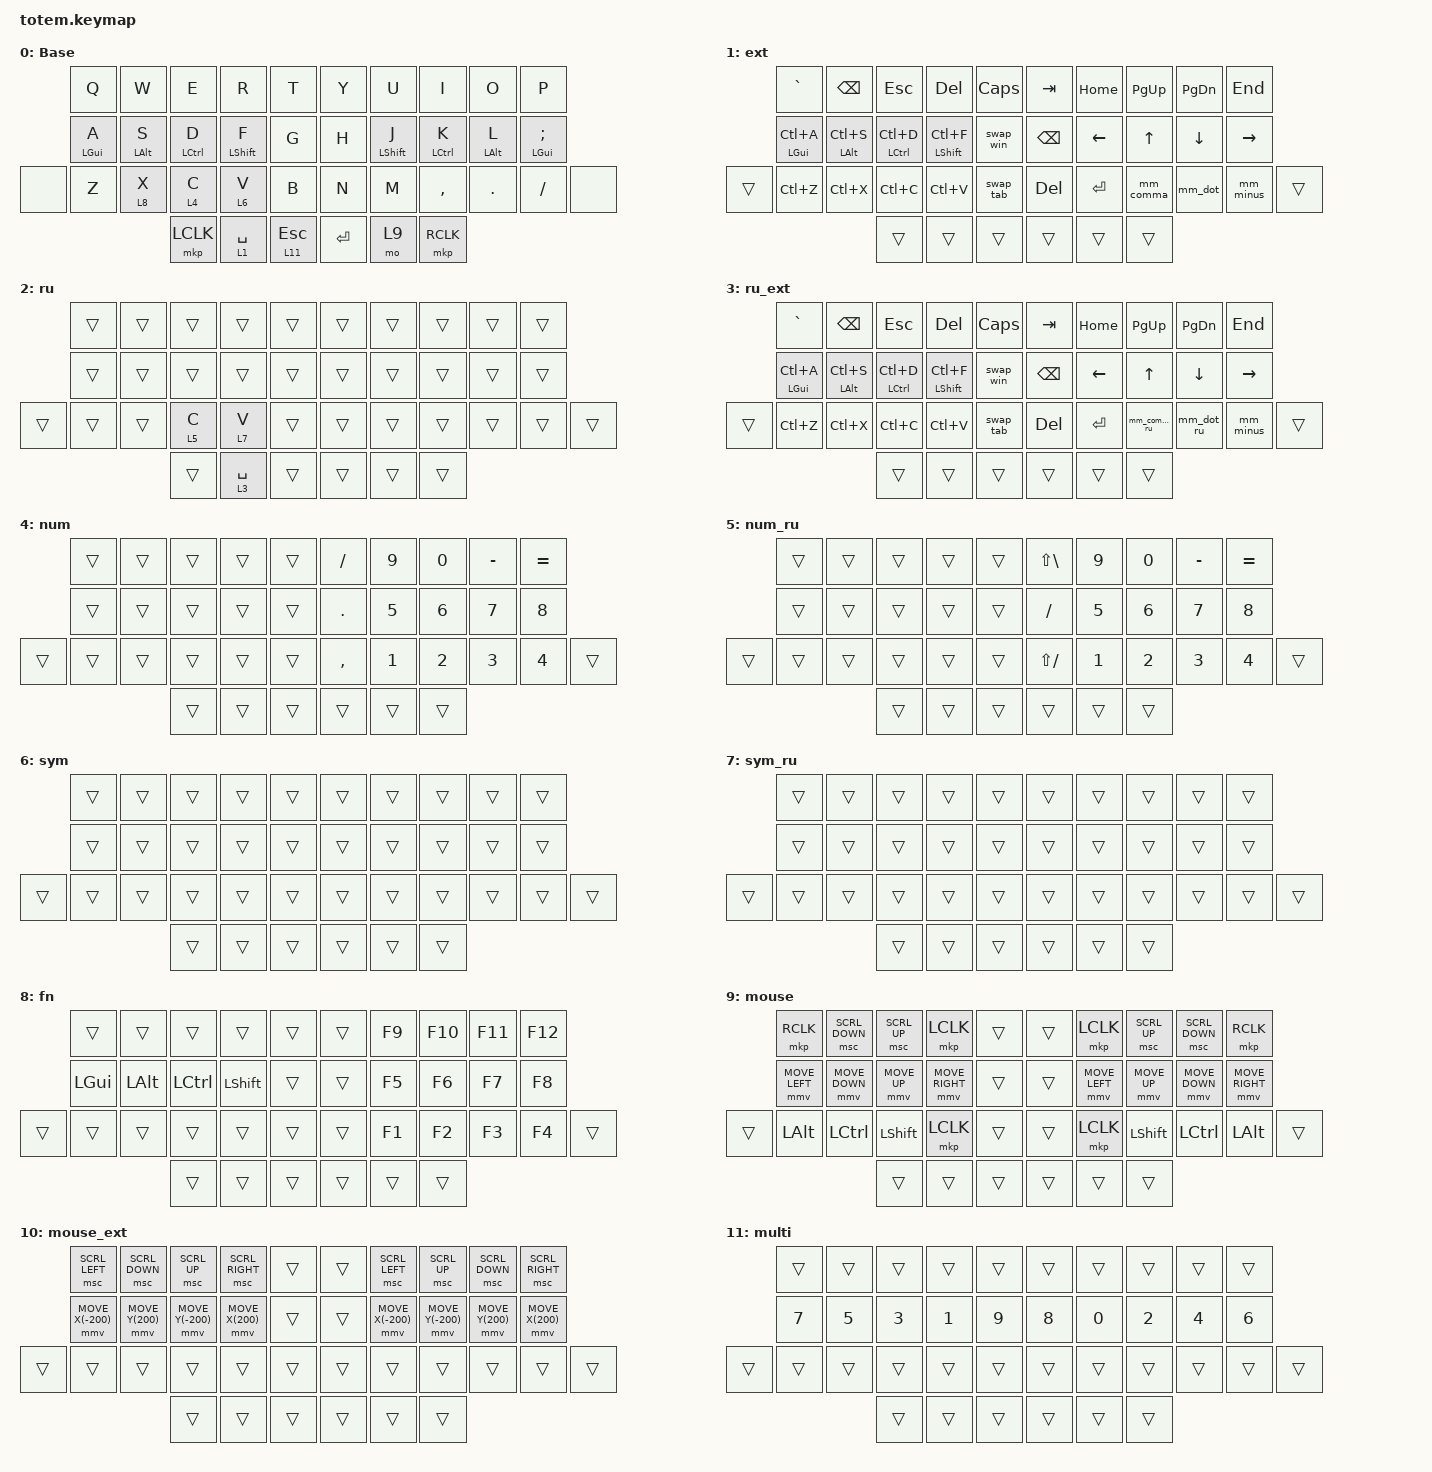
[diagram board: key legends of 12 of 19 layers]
//
//                                                        ▀▀▀▀▀     ▀▀▀▀▀          ▀▀█▀▀
//                                                        ▄▀▀▀▄  ▄  ▄▀▀▀▄  ▄  ▄▀▀▀▄  █  ▄▀▀▀▄
//                                                        █   █  █  █   █  █  █   █  █  █   █
//                                                         ▀▀▀   █   ▀▀▀   █   ▀▀▀   ▀   ▀▀▀
//                                                               █      ▄▄▄█▄▄▄    █   █
//                                                               ▀      █  █  █     █▄█
//                                                             ▀▀▀▀▀    █  █  █      ▀
//                                                                      ▀  ▀  ▀
//
// ▄▄▄▄▄▄▄▄▄▄▄▄▄▄▄▄▄▄▄▄▄▄▄▄▄▄▄▄▄▄▄▄▄▄▄▄▄▄▄▄▄▄▄▄▄▄▄▄▄▄▄▄▄▄▄▄▄▄▄▄▄▄▄▄▄▄▄▄▄▄▄▄▄▄▄▄▄▄▄▄▄▄▄▄▄▄▄▄▄▄▄▄▄▄▄▄▄▄▄▄▄▄▄▄▄▄▄▄▄▄▄▄▄▄▄▄▄▄▄▄▄▄▄▄▄▄▄▄▄▄▄▄▄▄▄▄▄▄▄▄▄▄▄▄▄▄▄▄▄

#define ZMK_POINTING_DEFAULT_MOVE_VAL 1200  // default: 600
#define ZMK_POINTING_DEFAULT_SCRL_VAL 20    // default: 10

#include <behaviors.dtsi>
#include <dt-bindings/zmk/keys.h>
#include <dt-bindings/zmk/pointing.h>

&mt {
    quick-tap-ms = <100>;
    global-quick-tap;
    flavor = "tap-preferred";
    tapping-term-ms = <170>;
};

&lt {
    tapping-term-ms = <240>;
    flavor = "balanced";
    quick-tap-ms = <150>;
};

/ {
    behaviors {
        tp: tap_preferred {
            compatible = "zmk,behavior-hold-tap";
            label = "TAP_PREFERRED";
            #binding-cells = <2>;
            tapping-term-ms = <150>;
            quick-tap-ms = <0>;
            flavor = "tap-preferred";
            bindings = <&kp>, <&kp>;
        };

        hml: home_row_mod_left {
            compatible = "zmk,behavior-hold-tap";
            #binding-cells = <2>;
            flavor = "balanced";
            require-prior-idle-ms = <150>;
            tapping-term-ms = <280>;
            quick-tap-ms = <175>;
            bindings = <&kp>, <&kp>;

            hold-trigger-key-positions = <5 6 7 8 9 9 15 16 18 19 26 27 28 29 30 31 35 36 37 17>;
            hold-trigger-on-release;
        };

        hmr: home_row_mod_right {
            compatible = "zmk,behavior-hold-tap";
            #binding-cells = <2>;
            flavor = "balanced";
            require-prior-idle-ms = <150>;
            tapping-term-ms = <280>;
            quick-tap-ms = <175>;
            bindings = <&kp>, <&kp>;

            hold-trigger-key-positions = <20 21 0 10 22 11 1 2 12 23 3 4 13 14 24 24 25 33 32 34>;
            hold-trigger-on-release;
        };

        num_word: num_word {
            compatible = "zmk,behavior-auto-layer";
            #binding-cells = <1>;
            continue-list = <BSPC DEL DOT COMMA PLUS MINUS STAR FSLH EQUAL>;
            ignore-numbers;
        };

        mm_comma: mm_comma {
            compatible = "zmk,behavior-mod-morph";
            label = "MM_COMMA";
            bindings = <&macro_comma>, <&kp SEMI>;

            #binding-cells = <0>;
            mods = <(MOD_LSFT|MOD_RSFT)>;
        };

        mm_comma_ru: mm_comma_ru {
            compatible = "zmk,behavior-mod-morph";
            label = "MM_COMMA_RU";
            bindings = <&macro_comma_ru>, <&kp SEMI>;

            #binding-cells = <0>;
            mods = <(MOD_LSFT|MOD_RSFT)>;
        };

        mm_dot: mm_dot {
            compatible = "zmk,behavior-mod-morph";
            label = "MM_DOT";
            bindings = <&macro_dot>, <&kp LS(SEMI)>;

            #binding-cells = <0>;
            mods = <(MOD_LSFT|MOD_RSFT)>;
        };

        mm_dot_ru: mm_dot_ru {
            compatible = "zmk,behavior-mod-morph";
            label = "MM_DOT_RU";
            bindings = <&macro_dot_ru>, <&kp LS(SEMI)>;

            #binding-cells = <0>;
            mods = <(MOD_LSFT|MOD_RSFT)>;
        };

        mm_minus: mm_minus {
            compatible = "zmk,behavior-mod-morph";
            label = "MM_MINUS";
            bindings = <&kp MINUS>, <&kp MINUS>;

            #binding-cells = <0>;
            mods = <(MOD_LSFT|MOD_RSFT)>;
        };

        swap_win: swapper_win {
            compatible = "zmk,behavior-tri-state";
            label = "SWAPPER_WIN";
            #binding-cells = <0>;
            bindings = <&kt LALT>, <&kp TAB>, <&kt LALT>;

            ignored-key-positions = <13>;
        };

        swap_tab: swapper_tab {
            compatible = "zmk,behavior-tri-state";
            label = "SWAPPER_TAB";
            #binding-cells = <0>;
            bindings = <&kt LCTRL>, <&kp TAB>, <&kt LCTRL>;

            ignored-key-positions = <13>;
        };
    };

    macros {
        macro_comma: macro_comma {
            compatible = "zmk,behavior-macro";
            #binding-cells = <0>;
            bindings = <&kp COMMA &kp SPACE>;
            label = "MACRO_COMMA";
        };

        macro_comma_ru: macro_comma_ru {
            compatible = "zmk,behavior-macro";
            #binding-cells = <0>;
            bindings = <&kp LS(SLASH) &kp SPACE>;
            label = "MACRO_COMMA_RU";
        };

        macro_dot: macro_dot {
            compatible = "zmk,behavior-macro";
            #binding-cells = <0>;
            bindings = <&kp DOT &kp SPACE &sk LSHFT>;
            label = "MACRO_DOT";
        };

        macro_dot_ru: macro_dot_ru {
            compatible = "zmk,behavior-macro";
            #binding-cells = <0>;
            bindings = <&kp SLASH &kp SPACE &sk LSHFT>;
            label = "MACRO_DOT_RU";
        };

        macro_lng: macro_lng {
            compatible = "zmk,behavior-macro";
            #binding-cells = <0>;
            bindings = <&kp CAPS &tog 2>;
            label = "MACRO_LNG";
        };

        macro_lng_en: macro_lng_sync {
            compatible = "zmk,behavior-macro";
            #binding-cells = <0>;
            bindings = <&kp CAPS &to 0>;
            label = "MACRO_LNG_SYNC";
        };

        macro_lt: macro_lt {
            compatible = "zmk,behavior-macro";
            #binding-cells = <0>;
            bindings = <&kp CAPS &kp LS(COMMA) &kp CAPS>;
            label = "MACRO_LT";
        };

        macro_gt: macro_gt {
            compatible = "zmk,behavior-macro";
            #binding-cells = <0>;
            bindings = <&kp CAPS &kp LS(DOT) &kp CAPS>;
            label = "MACRO_GT";
        };
    };

    combos {
        compatible = "zmk,combos";

        combo_lng_l {
            bindings = <&macro_lng>;
            key-positions = <3 13>;
        };

        combo_lng_r {
            bindings = <&macro_lng>;
            key-positions = <6 16>;
        };

        combo_esc {
            bindings = <&kp ESC>;
            key-positions = <2 12>;
        };

        combo_ret {
            bindings = <&kp RET>;
            key-positions = <16 27>;
        };

        combo_bspc {
            bindings = <&kp BACKSPACE>;
            key-positions = <15 16>;
        };

        combo_spc {
            bindings = <&kp SPACE>;
            key-positions = <13 24>;
        };

        combo_num_word_en {
            bindings = <&num_word 4>;
            key-positions = <7 17>;
            layers = <0>;
        };

        combo_caps_word {
            bindings = <&caps_word>;
            key-positions = <8 18>;
        };

        combo_ins {
            bindings = <&kp INS>;
            key-positions = <15 26>;
        };

        combo_mouse_l {
            bindings = <&tog 3>;
            key-positions = <3 4>;
        };

        combo_mouse_r {
            bindings = <&tog 3>;
            key-positions = <6 5>;
        };

        combo_num_word_ru {
            bindings = <&num_word 5>;
            key-positions = <17 7>;
            layers = <15>;
        };

        combo_lbkt {
            bindings = <&kp LBKT>;
            key-positions = <9 8>;
        };

        combo_sqt {
            bindings = <&kp SQT>;
            key-positions = <18 19>;
        };

        combo_rbkt {
            bindings = <&kp RBKT>;
            key-positions = <29 30>;
        };
    };

    keymap {
        compatible = "zmk,keymap";

        Base {
            display-name = "Base";
            bindings = <
       &kp Q        &kp W        &kp E         &kp R          &kp T         &kp Y    &kp U         &kp I         &kp O        &kp P
       &hml LGUI A  &hml LALT S  &hml LCTRL D  &hml LSHIFT F  &kp G         &kp H    &hmr LSHFT J  &hmr LCTRL K  &hmr LALT L  &hmr LGUI SEMICOLON
&none  &kp Z        &lt 8 X      &lt 4 C       &lt 6 V        &kp B         &kp N    &kp M         &kp COMMA     &kp DOT      &kp SLASH            &none
                                 &mkp LCLK     &lt 1 SPACE    &lt 11 ESC    &kp RET  &mo 9         &mkp RCLK
            >;
        };

        ext {
            bindings = <
        &kp GRAVE       &kp BACKSPACE   &kp ESC          &kp DEL          &kp CAPS     &kp TAB        &kp HOME  &kp PG_UP  &kp PG_DN  &kp END
        &tp LGUI LC(A)  &tp LALT LC(S)  &tp LCTRL LC(D)  &tp LSHFT LC(F)  &swap_win    &kp BACKSPACE  &kp LEFT  &kp UP     &kp DOWN   &kp RIGHT
&trans  &kp LC(Z)       &kp LC(X)       &kp LC(C)        &kp LC(V)        &swap_tab    &kp DEL        &kp RET   &mm_comma  &mm_dot    &mm_minus  &trans
                                        &trans           &trans           &trans       &trans         &trans    &trans
            >;
        };

        ru {
            bindings = <
        &trans  &trans  &trans   &trans       &trans    &trans  &trans  &trans  &trans  &trans
        &trans  &trans  &trans   &trans       &trans    &trans  &trans  &trans  &trans  &trans
&trans  &trans  &trans  &lt 5 C  &lt 7 V      &trans    &trans  &trans  &trans  &trans  &trans  &trans
                        &trans   &lt 3 SPACE  &trans    &trans  &trans  &trans
            >;
        };

        ru_ext {
            bindings = <
        &kp GRAVE       &kp BACKSPACE   &kp ESC          &kp DEL          &kp CAPS     &kp TAB        &kp HOME  &kp PG_UP     &kp PG_DN   &kp END
        &tp LGUI LC(A)  &tp LALT LC(S)  &tp LCTRL LC(D)  &tp LSHFT LC(F)  &swap_win    &kp BACKSPACE  &kp LEFT  &kp UP        &kp DOWN    &kp RIGHT
&trans  &kp LC(Z)       &kp LC(X)       &kp LC(C)        &kp LC(V)        &swap_tab    &kp DEL        &kp RET   &mm_comma_ru  &mm_dot_ru  &mm_minus  &trans
                                        &trans           &trans           &trans       &trans         &trans    &trans
            >;
        };

        num {
            bindings = <
        &trans  &trans  &trans  &trans  &trans    &kp SLASH  &kp N9  &kp N0  &kp MINUS  &kp EQUAL
        &trans  &trans  &trans  &trans  &trans    &kp DOT    &kp N5  &kp N6  &kp N7     &kp N8
&trans  &trans  &trans  &trans  &trans  &trans    &kp COMMA  &kp N1  &kp N2  &kp N3     &kp N4     &trans
                        &trans  &trans  &trans    &trans     &trans  &trans
            >;
        };

        num_ru {
            bindings = <
        &trans  &trans  &trans  &trans  &trans    &kp LS(BACKSLASH)  &kp N9  &kp N0  &kp MINUS  &kp EQUAL
        &trans  &trans  &trans  &trans  &trans    &kp SLASH          &kp N5  &kp N6  &kp N7     &kp N8
&trans  &trans  &trans  &trans  &trans  &trans    &kp LS(SLASH)      &kp N1  &kp N2  &kp N3     &kp N4     &trans
                        &trans  &trans  &trans    &trans             &trans  &trans
            >;
        };

        sym {
            bindings = <
        &trans  &trans  &trans  &trans  &trans    &trans  &trans  &trans  &trans  &trans
        &trans  &trans  &trans  &trans  &trans    &trans  &trans  &trans  &trans  &trans
&trans  &trans  &trans  &trans  &trans  &trans    &trans  &trans  &trans  &trans  &trans  &trans
                        &trans  &trans  &trans    &trans  &trans  &trans
            >;
        };

        sym_ru {
            bindings = <
        &trans  &trans  &trans  &trans  &trans    &trans  &trans  &trans  &trans  &trans
        &trans  &trans  &trans  &trans  &trans    &trans  &trans  &trans  &trans  &trans
&trans  &trans  &trans  &trans  &trans  &trans    &trans  &trans  &trans  &trans  &trans  &trans
                        &trans  &trans  &trans    &trans  &trans  &trans
            >;
        };

        fn {
            bindings = <
        &trans    &trans    &trans     &trans     &trans    &trans  &kp F9  &kp F10  &kp F11  &kp F12
        &kp LGUI  &kp LALT  &kp LCTRL  &kp LSHFT  &trans    &trans  &kp F5  &kp F6   &kp F7   &kp F8
&trans  &trans    &trans    &trans     &trans     &trans    &trans  &kp F1  &kp F2   &kp F3   &kp F4   &trans
                            &trans     &trans     &trans    &trans  &trans  &trans
            >;
        };

        mouse {
            bindings = <
        &mkp RCLK       &msc SCRL_DOWN  &msc SCRL_UP  &mkp LCLK        &trans    &trans  &mkp LCLK       &msc SCRL_UP  &msc SCRL_DOWN  &mkp RCLK
        &mmv MOVE_LEFT  &mmv MOVE_DOWN  &mmv MOVE_UP  &mmv MOVE_RIGHT  &trans    &trans  &mmv MOVE_LEFT  &mmv MOVE_UP  &mmv MOVE_DOWN  &mmv MOVE_RIGHT
&trans  &kp LALT        &kp LCTRL       &kp LSHFT     &mkp LCLK        &trans    &trans  &mkp LCLK       &kp LSHFT     &kp LCTRL       &kp LALT         &trans
                                        &trans        &trans           &trans    &trans  &trans          &trans
            >;
        };

        mouse_ext {
            bindings = <
        &msc SCRL_LEFT     &msc SCRL_DOWN    &msc SCRL_UP       &msc SCRL_RIGHT   &trans    &trans  &msc SCRL_LEFT     &msc SCRL_UP       &msc SCRL_DOWN    &msc SCRL_RIGHT
        &mmv MOVE_X(-200)  &mmv MOVE_Y(200)  &mmv MOVE_Y(-200)  &mmv MOVE_X(200)  &trans    &trans  &mmv MOVE_X(-200)  &mmv MOVE_Y(-200)  &mmv MOVE_Y(200)  &mmv MOVE_X(200)
&trans  &trans             &trans            &trans             &trans            &trans    &trans  &trans             &trans             &trans            &trans            &trans
                                             &trans             &trans            &trans    &trans  &trans             &trans
            >;
        };

        multi {
            bindings = <
        &trans  &trans  &trans  &trans  &trans    &trans  &trans  &trans  &trans  &trans
        &kp N7  &kp N5  &kp N3  &kp N1  &kp N9    &kp N8  &kp N0  &kp N2  &kp N4  &kp N6
&trans  &trans  &trans  &trans  &trans  &trans    &trans  &trans  &trans  &trans  &trans  &trans
                        &trans  &trans  &trans    &trans  &trans  &trans
            >;
        };

        multi_ext {
            bindings = <
        &trans  &trans  &trans  &trans  &trans    &trans  &trans  &trans  &trans  &trans
        &trans  &trans  &trans  &trans  &trans    &trans  &trans  &trans  &trans  &trans
&trans  &trans  &trans  &trans  &trans  &trans    &trans  &trans  &trans  &trans  &trans  &trans
                        &trans  &trans  &trans    &trans  &trans  &trans
            >;
        };

        sys {
            bindings = <
             &trans  &trans  &trans  &trans  &trans    &trans  &trans  &trans  &trans  &trans
             &trans  &trans  &trans  &trans  &trans    &trans  &trans  &trans  &trans  &trans
&bootloader  &trans  &trans  &trans  &trans  &trans    &trans  &trans  &trans  &trans  &trans  &bootloader
                             &trans  &trans  &trans    &trans  &trans  &trans
            >;
        };

        Nav {
            display-name = "Nav";
            bindings = <
              &kp TILDE       &trans     &kp UP_ARROW  &trans     &kp LBRC    &kp RBRC  &kp NUMBER_7  &kp NUMBER_8  &kp NUMBER_9  &kp NUMBER_0
              &kp LEFT_SHIFT  &kp LEFT   &kp DOWN      &kp RIGHT  &kp LBKT    &kp RBKT  &kp NUMBER_4  &kp NUMBER_5  &kp NUMBER_6  &kp MINUS
&kp LEFT_ALT  &kp LEFT_WIN    &kp MINUS  &trans        &kp PLUS   &kp LPAR    &kp RPAR  &kp NUMBER_1  &kp NUMBER_2  &kp NUMBER_3  &kp KP_MULTIPLY  &kp PLUS
                                         &trans        &trans     &trans      &trans    &trans        &kp DOT
            >;
        };

        Sym {
            display-name = "Sym";
            bindings = <
                &kp EXCL  &kp AT  &kp HASH  &kp DOLLAR  &kp PERCENT    &kp CARET  &kp AMPERSAND  &kp KP_ASTERISK  &kp SQT  &kp DQT
                &trans    &trans  &trans    &trans      &trans         &trans     &trans         &trans           &trans   &trans
&studio_unlock  &trans    &trans  &trans    &trans      &trans         &kp UNDER  &kp EQUAL      &trans           &trans   &kp SLASH  &kp HOME
                                  &trans    &trans      &trans         &trans     &trans         &trans
            >;
        };

        Fun {
            display-name = "Fun";
            bindings = <
        &bootloader  &trans  &trans  &trans  &to 17    &trans  &trans  &trans  &kp END  &kp F1
        &trans       &trans  &trans  &trans  &trans    &trans  &trans  &trans  &trans   &kp F10
&trans  &trans       &trans  &trans  &trans  &trans    &trans  &trans  &trans  &trans   &kp F20  &kp F7
                             &trans  &trans  &trans    &trans  &trans  &trans
            >;
        };

        Gaming {
            display-name = "Game";
            bindings = <
            &kp Z           &kp X  &kp C      &kp V         &sl 18    &trans  &trans  &trans  &trans  &trans
            &kp TAB         &kp Q  &kp W      &kp E         &kp R     &trans  &trans  &trans  &trans  &trans
&kp ESCAPE  &kp LEFT_SHIFT  &kp A  &kp S      &kp D         &kp F     &trans  &trans  &trans  &trans  &trans  &trans
                                   &kp LCTRL  &kp LEFT_ALT  &trans    &trans  &trans  &trans
            >;
        };

        Gaming+ {
            display-name = "Game+";
            bindings = <
        &kp F10  &kp NUMBER_1  &kp NUMBER_2  &kp NUMBER_3  &kp T     &kp RA(RC(Y))  &kp RA(RC(U))  &trans  &trans  &kp LC(RA(DEL))
        &kp L    &kp O         &kp Y         &kp K         &kp G     &kp F5         &kp F7         &trans  &trans  &kp F12
&trans  &to 0    &trans        &trans        &trans        &trans    &trans         &trans         &trans  &trans  &kp F22          &kp LA(F4)
                               &kp J         &kp I         &kp M     &trans         &trans         &trans
            >;
        };
    };
};
